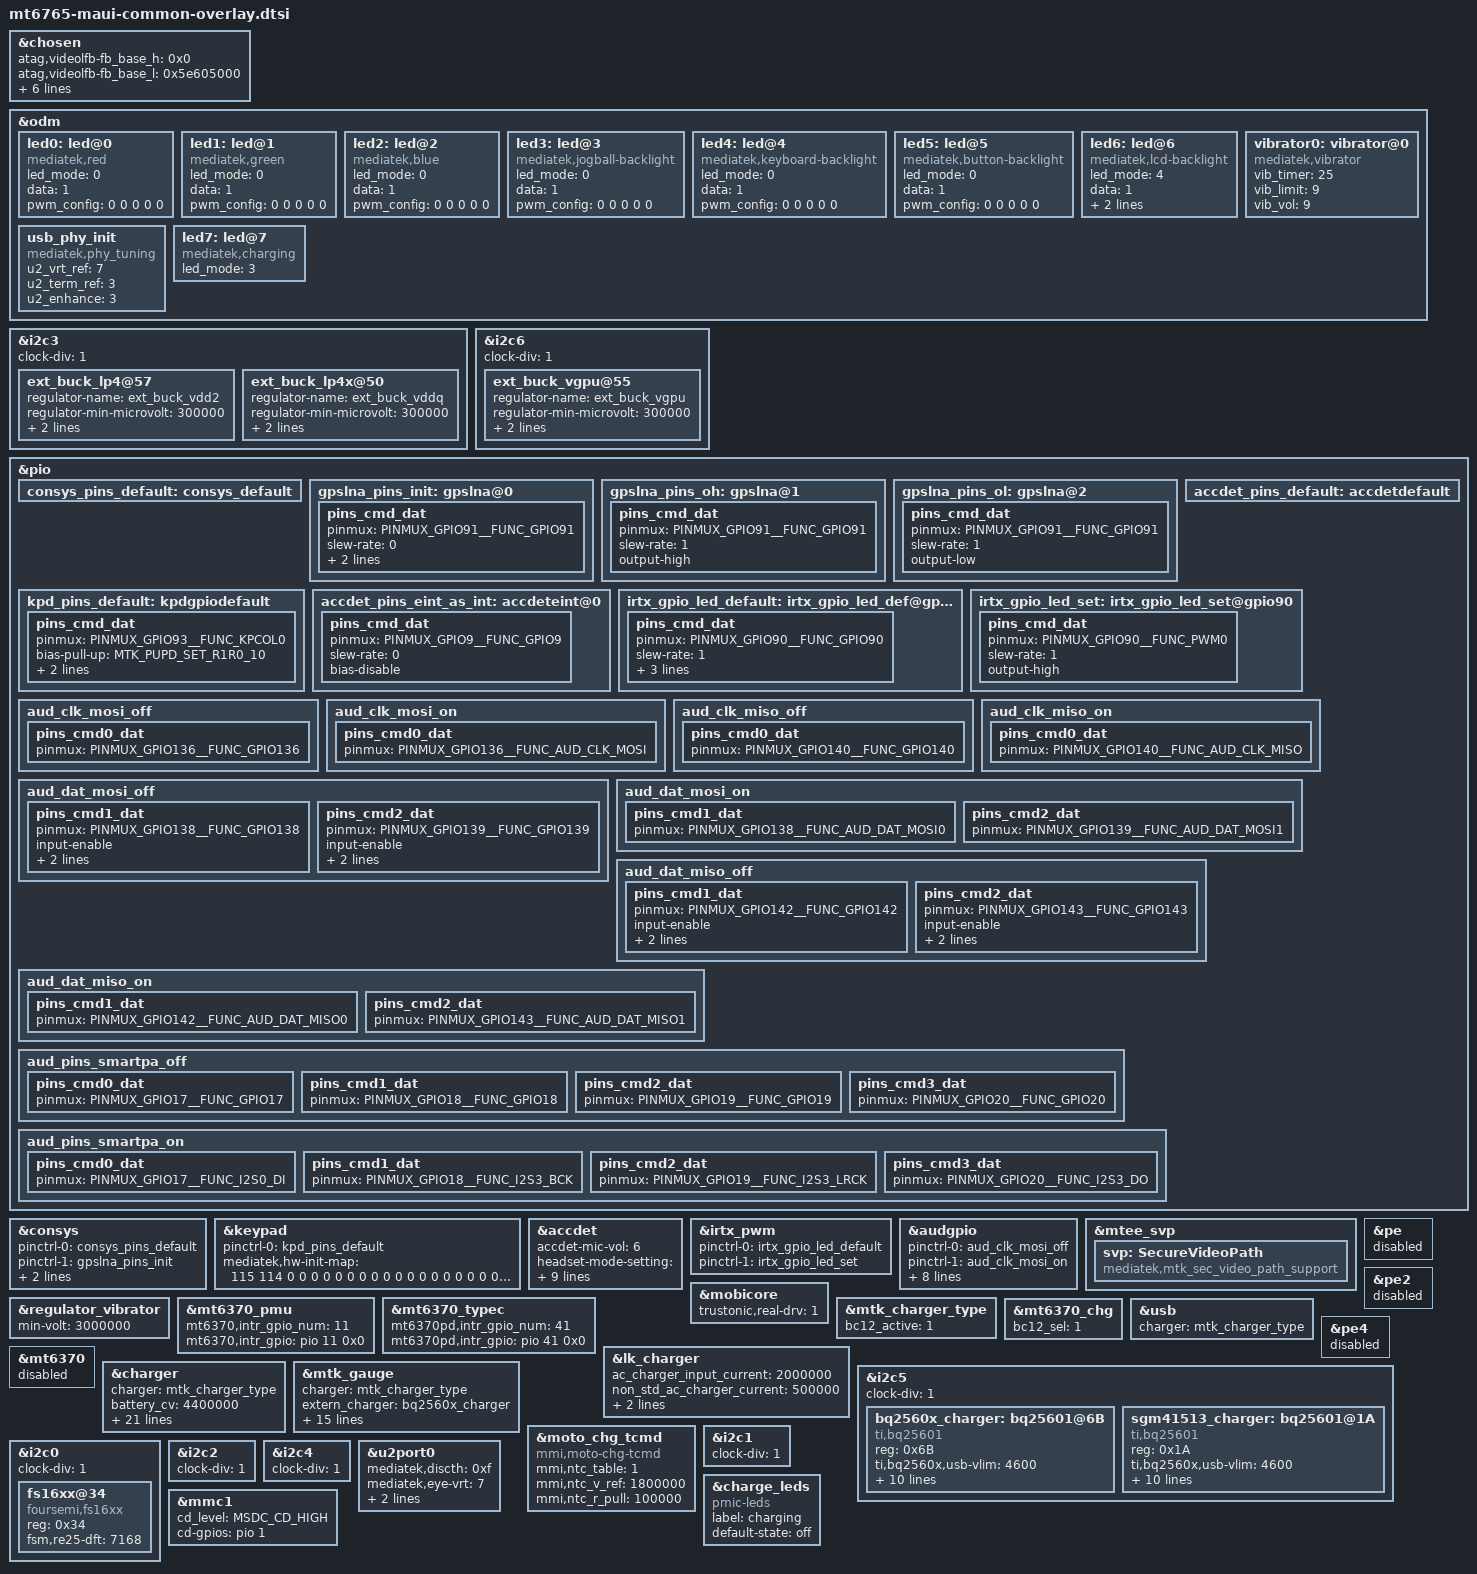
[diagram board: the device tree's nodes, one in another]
/* Copyright (c) 2022, Motorola Mobility Inc. All rights reserved.
 *
 * This program is free software; you can redistribute it and/or modify
 * it under the terms of the GNU General Public License version 2 and
 * only version 2 as published by the Free Software Foundation.
 *
 * This program is distributed in the hope that it will be useful,
 * but WITHOUT ANY WARRANTY; without even the implied warranty of
 * MERCHANTABILITY or FITNESS FOR A PARTICULAR PURPOSE.  See the
 * GNU General Public License for more details.
 */

#include "mt6765-moto-common-overlay.dtsi"
#include "mt6765-moto-maui-fps.dtsi"
#include "mt6765-moto-memory.dtsi"
#include <dt-bindings/interrupt-controller/arm-gic.h>
#include <dt-bindings/interrupt-controller/irq.h>
#include <dt-bindings/pinctrl/mt6765-pinfunc.h>
#include <dt-bindings/clock/mt6765-clk.h>
#include <dt-bindings/mmc/mt6765-msdc.h>
#include <dt-bindings/gpio/gpio.h>
#include "maui-display.dtsi"

/* chosen */
&chosen {

	/* fpga may has no lk, we need to specify display info here */
	/* fb buffer is reserved using this dts by memory node above */
	atag,videolfb-fb_base_h = <0x0>;
	atag,videolfb-fb_base_l = <0x5e605000>;
	atag,videolfb-islcmfound = <1>;
	/* because no lk, so lcm is not inited */
	atag,videolfb-islcm_inited = <0>;
	atag,videolfb-fps= <6000>;
	atag,videolfb-vramSize= <0x017bb000>;
	atag,videolfb-lcmname= "nt35695B_fhd_dsi_cmd_auo_rt5081_drv";
};

&odm {
	led0:led@0 {
		compatible = "mediatek,red";
		led_mode = <0>;
		data = <1>;
		pwm_config = <0 0 0 0 0>;
	};
	led1:led@1 {
		compatible = "mediatek,green";
		led_mode = <0>;
		data = <1>;
		pwm_config = <0 0 0 0 0>;
	};
	led2:led@2 {
		compatible = "mediatek,blue";
		led_mode = <0>;
		data = <1>;
		pwm_config = <0 0 0 0 0>;
	};
	led3:led@3 {
		compatible = "mediatek,jogball-backlight";
		led_mode = <0>;
		data = <1>;
		pwm_config = <0 0 0 0 0>;
	};
	led4:led@4 {
		compatible = "mediatek,keyboard-backlight";
		led_mode = <0>;
		data = <1>;
		pwm_config = <0 0 0 0 0>;
	};
	led5:led@5 {
		compatible = "mediatek,button-backlight";
		led_mode = <0>;
		data = <1>;
		pwm_config = <0 0 0 0 0>;
	};
	led6:led@6 {
		compatible = "mediatek,lcd-backlight";
		led_mode = <5>;
		data = <1>;
		pwm_config = <0 3 0 0 0>;
	};
	vibrator0:vibrator@0 {
		compatible = "mediatek,vibrator";
		vib_timer = <25>;
		vib_limit = <9>;
		vib_vol= <9>;
	};
	usb_phy_init:usb_phy_init {
		compatible = "mediatek,phy_tuning";
		u2_vrt_ref = <7>;
		u2_term_ref = <3>;
		u2_enhance = <3>;
		status = "okay";
	};

};

&i2c3 {
	ext_buck_lp4@57 {
		regulator-name ="ext_buck_vdd2";
		regulator-min-microvolt = <300000>;
		regulator-max-microvolt = <1300000>;
		vsel_pin = <0>;
	};

	ext_buck_lp4x@50 {
		regulator-name ="ext_buck_vddq";
		regulator-min-microvolt = <300000>;
		regulator-max-microvolt = <1300000>;
		vsel_pin = <1>;
	};
};

&i2c6 {
	ext_buck_vgpu@55 {
		regulator-name ="ext_buck_vgpu";
		regulator-min-microvolt = <300000>;
		regulator-max-microvolt = <1300000>;
		vsel_pin = <2>;
	};
};

/* CONSYS GPIO standardization */
&pio {
	consys_pins_default: consys_default {
	};
	gpslna_pins_init: gpslna@0 {
		pins_cmd_dat {
			pinmux = <PINMUX_GPIO91__FUNC_GPIO91>;
			slew-rate = <0>;
			bias-disable;
			output-low;
		};
	};
	gpslna_pins_oh: gpslna@1 {
		pins_cmd_dat {
			pinmux = <PINMUX_GPIO91__FUNC_GPIO91>;
			slew-rate = <1>;
			output-high;
		};
	};
	gpslna_pins_ol: gpslna@2 {
		pins_cmd_dat {
			pinmux = <PINMUX_GPIO91__FUNC_GPIO91>;
			slew-rate = <1>;
			output-low;
		};
	};
};
&consys {
	pinctrl-names = "default", "gps_lna_state_init",
		"gps_lna_state_oh", "gps_lna_state_ol";
	pinctrl-0 = <&consys_pins_default>;
	pinctrl-1 = <&gpslna_pins_init>;
	pinctrl-2 = <&gpslna_pins_oh>;
	pinctrl-3 = <&gpslna_pins_ol>;
	status = "okay";
};
/* CONSYS end */

&keypad {
	pinctrl-names = "default";
	pinctrl-0 = <&kpd_pins_default>;
};

&pio {
	kpd_pins_default: kpdgpiodefault {
		pins_cmd_dat {
			pinmux = <PINMUX_GPIO93__FUNC_KPCOL0>;
			bias-pull-up = <MTK_PUPD_SET_R1R0_10>;
			output-low;
			input-schmitt-enable;
		};
	};
};


/* accdet start */
&accdet {
	accdet-mic-vol = <6>;
	headset-mode-setting = <0x500 0x500 1 0x1f0 0x800 0x800 0x20 0x44>;
	accdet-plugout-debounce = <1>;
	accdet-mic-mode = <1>;
	headset-eint-level-pol = <8>;
	headset-three-key-threshold = <0 80 220 400>;
	headset-three-key-threshold-CDD = <0 121 192 600>;
	headset-four-key-threshold = <0 58 121 192 400>;
	pinctrl-names = "default", "state_eint_as_int";
	pinctrl-0 = <&accdet_pins_default>;
	pinctrl-1 = <&accdet_pins_eint_as_int>;
	status = "okay";
};
&pio {
	accdet_pins_default: accdetdefault {
	};
	accdet_pins_eint_as_int: accdeteint@0 {
		pins_cmd_dat {
			pinmux = <PINMUX_GPIO9__FUNC_GPIO9>;
			slew-rate = <0>;
			bias-disable;
		};
	};
};
/* accdet end */

/* IRTX GPIO end */
&irtx_pwm {
	pinctrl-names = "irtx_gpio_led_default", "irtx_gpio_led_set";
	pinctrl-0 = <&irtx_gpio_led_default>;
	pinctrl-1 = <&irtx_gpio_led_set>;
	status = "okay";
};
&pio {
	irtx_gpio_led_default:irtx_gpio_led_def@gpio90 {
		pins_cmd_dat {
			pinmux = <PINMUX_GPIO90__FUNC_GPIO90>;
			slew-rate = <1>;
			bias-disable;
			output-low;
			input-schmitt-enable = <0>;
		};
	};

	irtx_gpio_led_set:irtx_gpio_led_set@gpio90 {
		pins_cmd_dat {
			pinmux = <PINMUX_GPIO90__FUNC_PWM0>;
			slew-rate = <1>;
			output-high;
		};
	};
};
/* IRTX GPIO Settings -End */

/* AUDIO GPIO standardization */
&audgpio {
	pinctrl-names = "aud_clk_mosi_off",
			"aud_clk_mosi_on",
			"aud_clk_miso_off",
			"aud_clk_miso_on",
			"aud_dat_mosi_off",
			"aud_dat_mosi_on",
			"aud_dat_miso_off",
			"aud_dat_miso_on",
			"aud_smartpa_off",
			"aud_smartpa_on";
	pinctrl-0 = <&aud_clk_mosi_off>;
	pinctrl-1 = <&aud_clk_mosi_on>;
	pinctrl-2 = <&aud_clk_miso_off>;
	pinctrl-3 = <&aud_clk_miso_on>;
	pinctrl-4 = <&aud_dat_mosi_off>;
	pinctrl-5 = <&aud_dat_mosi_on>;
	pinctrl-6 = <&aud_dat_miso_off>;
	pinctrl-7 = <&aud_dat_miso_on>;
	pinctrl-8 = <&aud_pins_smartpa_off>;
	pinctrl-9 = <&aud_pins_smartpa_on>;
	status = "okay";
};

&pio {
	aud_clk_mosi_off: aud_clk_mosi_off {
		pins_cmd0_dat {
			pinmux = <PINMUX_GPIO136__FUNC_GPIO136>;
		};
	};

	aud_clk_mosi_on: aud_clk_mosi_on {
		pins_cmd0_dat {
			pinmux = <PINMUX_GPIO136__FUNC_AUD_CLK_MOSI>;
		};
	};

	aud_clk_miso_off: aud_clk_miso_off {
		pins_cmd0_dat {
			pinmux = <PINMUX_GPIO140__FUNC_GPIO140>;
		};
	};

	aud_clk_miso_on: aud_clk_miso_on {
		pins_cmd0_dat {
			pinmux = <PINMUX_GPIO140__FUNC_AUD_CLK_MISO>;
		};
	};

	aud_dat_mosi_off: aud_dat_mosi_off {
		pins_cmd1_dat {
			pinmux = <PINMUX_GPIO138__FUNC_GPIO138>;
			input-enable;
			slew-rate = <0>;
			bias-disable;
		};
		pins_cmd2_dat {
			pinmux = <PINMUX_GPIO139__FUNC_GPIO139>;
			input-enable;
			slew-rate = <0>;
			bias-disable;
		};
	};

	aud_dat_mosi_on: aud_dat_mosi_on {
		pins_cmd1_dat {
			pinmux = <PINMUX_GPIO138__FUNC_AUD_DAT_MOSI0>;
		};
		pins_cmd2_dat {
			pinmux = <PINMUX_GPIO139__FUNC_AUD_DAT_MOSI1>;
		};
	};

	aud_dat_miso_off: aud_dat_miso_off {
		pins_cmd1_dat {
			pinmux = <PINMUX_GPIO142__FUNC_GPIO142>;
			input-enable;
			slew-rate = <0>;
			bias-disable;
		};
		pins_cmd2_dat {
			pinmux = <PINMUX_GPIO143__FUNC_GPIO143>;
			input-enable;
			slew-rate = <0>;
			bias-disable;
		};
	};

	aud_dat_miso_on: aud_dat_miso_on {
		pins_cmd1_dat {
			pinmux = <PINMUX_GPIO142__FUNC_AUD_DAT_MISO0>;
		};
		pins_cmd2_dat {
			pinmux = <PINMUX_GPIO143__FUNC_AUD_DAT_MISO1>;
		};
	};

	aud_pins_smartpa_off: aud_pins_smartpa_off {
		pins_cmd0_dat {
			pinmux = <PINMUX_GPIO17__FUNC_GPIO17>;
		};
		pins_cmd1_dat {
			pinmux = <PINMUX_GPIO18__FUNC_GPIO18>;
		};
		pins_cmd2_dat {
			pinmux = <PINMUX_GPIO19__FUNC_GPIO19>;
		};
		pins_cmd3_dat {
			pinmux = <PINMUX_GPIO20__FUNC_GPIO20>;
		};
	};

	aud_pins_smartpa_on: aud_pins_smartpa_on {
		pins_cmd0_dat {
			pinmux = <PINMUX_GPIO17__FUNC_I2S0_DI>;
		};
		pins_cmd1_dat {
			pinmux = <PINMUX_GPIO18__FUNC_I2S3_BCK>;
		};
		pins_cmd2_dat {
			pinmux = <PINMUX_GPIO19__FUNC_I2S3_LRCK>;
		};
		pins_cmd3_dat {
			pinmux = <PINMUX_GPIO20__FUNC_I2S3_DO>;
		};
	};
};
/* AUDIO end */

/* SVP */
&mtee_svp {
	svp: SecureVideoPath {
		compatible = "mediatek,mtk_sec_video_path_support";
	};
};

/* Trustonic Mobicore real driver */
&mobicore {
	trustonic,real-drv = <1>;
};

&regulator_vibrator {
	min-volt = <3000000>;
};

&mt6370_pmu {
	mt6370,intr_gpio_num = <11>; /* direct defined GPIO num */
	mt6370,intr_gpio = <&pio 11 0x0>;
};

&mt6370_typec {
	mt6370pd,intr_gpio_num = <41>; /* direct defined GPIO num */
	mt6370pd,intr_gpio = <&pio 41 0x0>;
};

&mtk_charger_type {
	bc12_active = <1>;
};

&mt6370_chg {
	bc12_sel = <1>;
};

&usb {
	charger = <&mtk_charger_type>;
};

&lk_charger {
	ac_charger_input_current = <2000000>;
	non_std_ac_charger_current = <500000>;
	charging_host_charger_current = <2000000>;
	ta_ac_charger_current = <2000000>;
};

&pe {
	status = "disable";
};
&pe2 {
	status = "disable";
};
&pe4 {
	status = "disable";
};

&mt6370 {
	status = "disable";
};

&i2c5 {
	bq2560x_charger:bq25601@6B {
		compatible = "ti,bq25601";
		reg = <0x6B>;
		ti,bq2560x,usb-vlim = <4600>;
		ti,bq2560x,usb-ilim = <2000>;
		ti,bq2560x,usb-vreg = <4400>;
		ti,bq2560x,usb-ichg = <2000>;
		ti,bq2560x,precharge-current = <256>;
		ti,bq2560x,termination-current = <120>;
		ti,bq2560x,boost-voltage = <4998>;
		ti,bq2560x,boost-current = <1200>;
		ti,bq2560x,enable_term;
		ti,bq2560x,stat-pin-ctrl = <3>;
		ti,bq2560x,vac-ovp-threshold = <6500>;

	};

	sgm41513_charger:bq25601@1A {
		compatible = "ti,bq25601";
		reg = <0x1A>;
		ti,bq2560x,usb-vlim = <4600>;
		ti,bq2560x,usb-ilim = <2000>;
		ti,bq2560x,usb-vreg = <4400>;
		ti,bq2560x,usb-ichg = <2000>;
		ti,bq2560x,precharge-current = <256>;
		ti,bq2560x,termination-current = <120>;
		ti,bq2560x,boost-voltage = <4998>;
		ti,bq2560x,boost-current = <1200>;
		ti,bq2560x,enable_term;
		ti,bq2560x,stat-pin-ctrl = <3>;
		ti,bq2560x,vac-ovp-threshold = <6500>;
	};
};

&charger {
	charger = <&mtk_charger_type>;
	/* common */
	battery_cv = <4400000>;
	max_charger_voltage = <6500000>;
	min_charger_voltage = <4600000>;

	/* charging current */
	usb_charger_current_suspend = <0>;
	usb_charger_current_unconfigured = <70000>;
	usb_charger_current_configured = <500000>;
	usb_charger_current = <500000>;
	ac_charger_current = <2000000>;
	ac_charger_input_current = <2000000>;
	non_std_ac_charger_current = <1000000>;
	charging_host_charger_current = <1500000>;
	apple_1_0a_charger_current = <650000>;
	apple_2_1a_charger_current = <800000>;
	ta_ac_charger_current = <2000000>;
	typec_limit_aicr = <3000000>;

	/*mmi config*/
	mmi,iterm-ma = <150>;
	mmi,mmi-temp-zones = <0 4200 1000 0>,
			<15 0 1000 1000>,
			<45 0 3000 3000>,
			<60 4200 2500 0>;
	mmi,enable-charging-limit;
	mmi,upper-limit-capacity = <65>;
	mmi,lower-limit-capacity = <60>;
};

&mtk_gauge {
	charger = <&mtk_charger_type>;
	extern_charger = <&bq2560x_charger>;
	extern_charger_sgm41513 = <&sgm41513_charger>;
	DIFFERENCE_FULLOCV_ITH = <80>;  /*gauge cut-off current, should overtop ieoc 50ma*/
	EMBEDDED_SEL = <(1)>;  /*embedded battery,don't remove the battery for user*/
	VIR_OLDOCV_DIFF_EMB = <3000>; /*0.1mv*/
	VIR_OLDOCV_DIFF_EMB_LT = <3000>; /*0.1mv*/

	/* battery prop */
	g_temperature = <(50) (25) (10) (0) (-10) (-25) (-30) (-35) (-40) (-45)>;
	g_FG_PSEUDO100 = <98 98 100 100
		98 98 100 100
		98 98 100 100
		98 98 100 100
		98 98 100 100
		100 100 100 100
		100 100 100 100
		100 100 100 100
		100 100 100 100
		100 100 100 100>;

	g_Q_MAX = <4822 4871 2490 1965
		4856 4936 2468 1984
		4854 4905 2310 1946
		4725 4794 1858 1873
		4856 4920 1843 1851
		2211 1652 1533 1541
		2201 1642 1523 1531
		2191 1632 1513 1521
		2181 1622 1503 1511
		2171 1612 1493 1501>;

	g_Q_MAX_H_CURRENT = <4822 4871 2190 1665
		4856 4936 2168 1684
		4854 4905 2010 1646
		4725 4794 1558 1573
		4856 4920 1543 1551
		2210 1650 1533 1541
		2200 1640 1523 1531
		2190 1630 1513 1521
		2180 1620 1503 1511
		2170 1610 1493 1501>;
	ACTIVE_TABLE = <(5)>;

	df-serialnum = "SB18C98449";
	#include "bat_setting/SWD_4V4_5000MAH.dtsi"
	#include "bat_setting/ATL_4V4_5000MAH.dtsi"
};

&odm {
	led7:led@7 {
		compatible = "mediatek,charging";
		led_mode = <3>;
	};
};

&moto_chg_tcmd {
                compatible = "mmi,moto-chg-tcmd";
                status = "okay";

                mmi,ntc_table = <1>;
                mmi,ntc_v_ref = <1800000>;
                mmi,ntc_r_pull = <100000>;
};

&led6 {
	led_mode = <4>;
	max-brightness = <1638>; /*2047*0.8*/
};

&i2c0 {
	fs16xx@34 {
		compatible = "foursemi,fs16xx";
		reg = <0x34>;
		fsm,re25-dft = <7168>;
		status = "okay";
	};
};

&i2c0 {
	clock-div = <1>;
};

&i2c1 {
	clock-div = <1>;
};

&i2c2 {
	clock-div = <1>;
};

&i2c3 {
	clock-div = <1>;
};

&i2c4 {
	clock-div = <1>;
};

&i2c5 {
	clock-div = <1>;
};

&i2c6 {
	clock-div = <1>;
};

&mmc1 {
	cd_level = /bits/ 8 <MSDC_CD_HIGH>;
	cd-gpios = <&pio 1 GPIO_ACTIVE_HIGH>;
};

&keypad {
	mediatek,hw-init-map = <115 114 0 0 0 0 0 0 0 0 0 0 0
		0 0 0 0 0 0 0 0 0 0 0 0 0 0
		0 0 0 0 0 0 0 0 0 0 0 0 0 0
		0 0 0 0 0 0 0 0 0 0 0 0 0 0
		0 0 0 0 0 0 0 0 0 0 0 0 0 0
		0 0 0>;
};

&u2port0 {
	mediatek,discth = <0xf>;
	mediatek,eye-vrt = <7>;
	mediatek,eye-term = <3>;
	mediatek,rev6 = <3>;
};

&charge_leds {
       compatible = "pmic-leds";
       label = "charging";
       default-state = "off";
};

//#include <k65v1_32_bsp/cust.dtsi>
#include "cust_mt6765_touch_maui_720x1600.dtsi"
#include "mt6765-maui-camera-sensor-overlay.dtsi"
//#include "cust_mt6765_touch_1080x1920.dtsi"
/*End of this file, DO NOT ADD ANYTHING HERE*/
